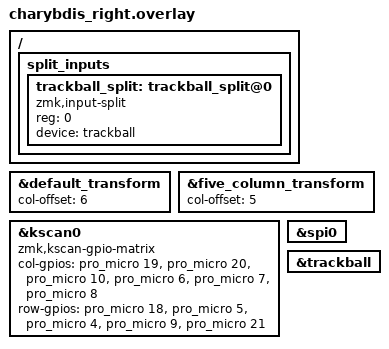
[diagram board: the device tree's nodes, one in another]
#include "charybdis.dtsi"
#include "charybdis_3610.dtsi"

&default_transform {
	col-offset = <6>;
};

&five_column_transform {
	col-offset = <5>;
};

&kscan0 {
	compatible = "zmk,kscan-gpio-matrix";
	
	col-gpios
		= <&pro_micro 19 (GPIO_ACTIVE_HIGH | GPIO_PULL_DOWN)>
		, <&pro_micro 20 (GPIO_ACTIVE_HIGH | GPIO_PULL_DOWN)>
		, <&pro_micro 10 (GPIO_ACTIVE_HIGH | GPIO_PULL_DOWN)>
		, <&pro_micro 6 (GPIO_ACTIVE_HIGH | GPIO_PULL_DOWN)>
		, <&pro_micro 7 (GPIO_ACTIVE_HIGH | GPIO_PULL_DOWN)>
		, <&pro_micro 8 (GPIO_ACTIVE_HIGH | GPIO_PULL_DOWN)>
		;

	row-gpios
		= <&pro_micro 18 GPIO_ACTIVE_HIGH>
		, <&pro_micro 5 GPIO_ACTIVE_HIGH>
		, <&pro_micro 4 GPIO_ACTIVE_HIGH>
		, <&pro_micro 9 GPIO_ACTIVE_HIGH>
		/* Row 4: large (4x6) variant's 4th main row. pro_micro 21 =
		   AVR F4, per Bastardkb's reference Elite-C matrix_pins
		   (rows: F4, F7, C6, D4, B5) -- verify against your board's
		   silkscreen/schematic if unsure. */
		, <&pro_micro 21 GPIO_ACTIVE_HIGH>
		;
};

&spi0 {
    status = "okay";
};

&trackball {
    status = "okay";
};

/* Native ZMK split input: forwards trackball events to the central (dongle).
   reg must match the zmk,input-split node in charybdis_dongle.overlay.
   Replaces zmk-split-peripheral-input-relay (relay-channel 102). */
/ {
	split_inputs {
		#address-cells = <1>;
		#size-cells = <0>;

		trackball_split: trackball_split@0 {
			compatible = "zmk,input-split";
			reg = <0>;
			device = <&trackball>;
		};
	};
};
